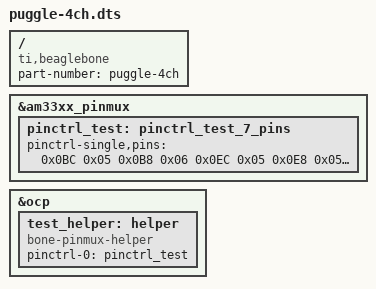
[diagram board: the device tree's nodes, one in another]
/*
	 -------------------------------------------------------------------------

	 This file is part of the Puggle Data Conversion and Processing System
	 Copyright (C) 2013 Puggle

	 -------------------------------------------------------------------------

	 Written in 2013 by: Yogi Patel <yapatel@gatech.edu>

	 To the extent possible under law, the author(s) have dedicated all copyright
	 and related and neighboring rights to this software to the public domain
	 worldwide. This software is distributed without any warranty.

	 You should have received a copy of the CC Public Domain Dedication along with
	 this software. If not, see <http://creativecommons.org/licenses/by-sa/3.0/legalcode>.
	 */

/dts-v1/;
/plugin/;

/ {
	compatible = "ti,beaglebone", "ti,beaglebone-black";

	/* identification */
	part-number = "puggle-4ch";

	fragment@0 {
		target = <&am33xx_pinmux>;
		__overlay__ {
			pinctrl_test: pinctrl_test_7_pins {
				pinctrl-single,pins = <
					0x0BC	0x05
					0x0B8	0x06
					0x0EC	0x05
					0x0E8	0x05
					0x0E4	0x05
					0x0E0	0x05
				>;
			};
		};
	};

	fragment@1 {
		target = <&ocp>;
		__overlay__ {
			test_helper: helper {
				compatible = "bone-pinmux-helper";
				pinctrl-names = "default";
				pinctrl-0 = <&pinctrl_test>;
				status = "okay";
			};
		};
	};
};
